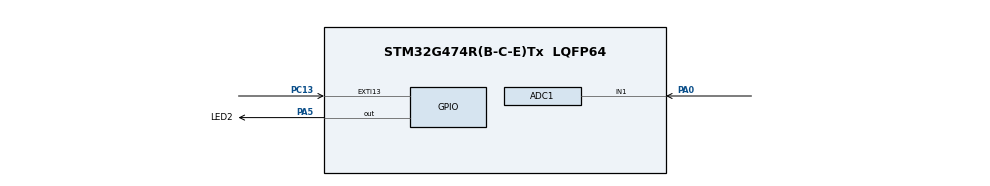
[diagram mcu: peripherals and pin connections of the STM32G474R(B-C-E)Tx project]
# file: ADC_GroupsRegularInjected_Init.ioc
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ADC1.Channel-16\#ChannelRegularConversion=ADC_CHANNEL_1
ADC1.Channel-IN=ADC_CHANNEL_VREFINT
ADC1.ContinuousConvMode=ENABLE
ADC1.DMAContinuousRequests=ENABLE
ADC1.DataAlign=ADC_DATAALIGN_RIGHT
ADC1.DiscontinuousConvMode=DISABLE
ADC1.EOCSelection=ADC_EOC_SINGLE_CONV
ADC1.EnableAnalogWatchDog1=false
ADC1.EnableAnalogWatchDog2=false
ADC1.EnableAnalogWatchDog3=false
ADC1.EnableInjectedConversion=ENABLE
ADC1.EnableInjectedOversampling=ENABLE
ADC1.EnableRegularConversion=ENABLE
ADC1.ExternalTrigConv=ADC_EXTERNALTRIG_T2_TRGO
ADC1.ExternalTrigConvEdge=ADC_EXTERNALTRIGCONVEDGE_RISING
ADC1.ExternalTrigInjecConv=ADC_INJECTED_SOFTWARE_START
ADC1.ExternalTrigInjecConvEdge=ADC_EXTERNALTRIGINJECCONV_EDGE_NONE
ADC1.InjNumberOfConversion=1
ADC1.InjOversamplingRatio=ADC_OVERSAMPLING_RATIO_2
ADC1.InjOversamplingRightShift=ADC_RIGHTBITSHIFT_NONE
ADC1.InjectedChannel-32\#ChannelInjectedConversion=ADC_CHANNEL_VREFINT
ADC1.InjectedConvMode=None
ADC1.InjectedOffsetNumber-32\#ChannelInjectedConversion=ADC_OFFSET_NONE
ADC1.InjectedRank-32\#ChannelInjectedConversion=1
ADC1.InjectedSamplingTime-32\#ChannelInjectedConversion=ADC_SAMPLETIME_640CYCLES_5
ADC1.LowPowerAutoWait=DISABLE
ADC1.NbrOfConversion=1
ADC1.OffsetNumber-16\#ChannelRegularConversion=ADC_OFFSET_NONE
ADC1.Overrun=ADC_OVR_DATA_OVERWRITTEN
ADC1.OversamplingMode=DISABLE
ADC1.Rank-16\#ChannelRegularConversion=1
ADC1.Resolution=ADC_RESOLUTION_12B
ADC1.SamplingTime-16\#ChannelRegularConversion=ADC_SAMPLETIME_47CYCLES_5
ADC1.ScanConvMode=ADC_SCAN_DISABLE
ADC1.injectedQueueMode=DISABLE
ADC1.master=1
Dma.ADC1.0.Direction=DMA_PERIPH_TO_MEMORY
Dma.ADC1.0.EventEnable=DISABLE
Dma.ADC1.0.Instance=DMA1_Channel1
Dma.ADC1.0.MemDataAlignment=DMA_MDATAALIGN_HALFWORD
Dma.ADC1.0.MemInc=DMA_MINC_ENABLE
Dma.ADC1.0.Mode=DMA_CIRCULAR
Dma.ADC1.0.PeriphDataAlignment=DMA_PDATAALIGN_HALFWORD
Dma.ADC1.0.PeriphInc=DMA_PINC_DISABLE
Dma.ADC1.0.Polarity=HAL_DMAMUX_REQ_GEN_RISING
Dma.ADC1.0.Priority=DMA_PRIORITY_HIGH
Dma.ADC1.0.RequestNumber=1
Dma.ADC1.0.SignalID=NONE
Dma.ADC1.0.SyncEnable=DISABLE
Dma.ADC1.0.SyncPolarity=HAL_DMAMUX_SYNC_NO_EVENT
Dma.ADC1.0.SyncRequestNumber=1
Dma.ADC1.0.SyncSignalID=NONE
Dma.Request0=ADC1
Mcu.Family=STM32G4
Mcu.Name=STM32G474R(B-C-E)Tx
Mcu.Package=LQFP64
NVIC.DMA1_Channel1_IRQn=true\:0\:0\:false\:false\:true\:false\:true\:true
NVIC.PriorityGroup=NVIC_PRIORITYGROUP_4
PA0.Mode=IN1-Single-Ended
PA0.Signal=ADC1_IN1
PA5.GPIO_Label=LED2
PA5.Signal=GPIO_Output
PC13.Signal=GPXTI13
ProjectManager.HeapSize=0x200
ProjectManager.StackSize=0x400
ProjectManager.TargetToolchain=EWARM V8.32
RCC.ADC12Freq_Value=150000000
RCC.ADC345Freq_Value=150000000
RCC.AHBFreq_Value=150000000
RCC.APB1Freq_Value=150000000
RCC.APB1TimFreq_Value=150000000
RCC.APB2Freq_Value=150000000
RCC.APB2TimFreq_Value=150000000
RCC.CortexFreq_Value=150000000
RCC.EXTERNAL_CLOCK_VALUE=12288000
RCC.HCLKFreq_Value=150000000
RCC.HSE_VALUE=24000000
RCC.HSI48_VALUE=16000000
RCC.HSI_VALUE=16000000
RCC.LSE_VALUE=32768
RCC.PLLM=RCC_PLLM_DIV4
RCC.PLLN=75
RCC.SYSCLKFreq_VALUE=150000000
RCC.SYSCLKSource=RCC_SYSCLKSOURCE_PLLCLK
RCC.USBFreq_Value=150000000
RCC.VCOOutputFreq_Value=300000000
TIM2.AutoReloadPreload=TIM_AUTORELOAD_PRELOAD_DISABLE
TIM2.ClockDivision=TIM_CLOCKDIVISION_DIV1
TIM2.CounterMode=TIM_COUNTERMODE_UP
TIM2.Period=(timer_reload - 1)
TIM2.Prescaler=(timer_prescaler - 1)
TIM2.TIM_MasterOutputTrigger=TIM_TRGO_UPDATE
TIM2.TIM_MasterSlaveMode=TIM_MASTERSLAVEMODE_DISABLE
TIM2.TIM_SlaveMode=TIM_SLAVEMODE_DISABLE
VP_ADC1_Vref_Input.Mode=IN-Vrefint
VP_SYS_VS_DBSignals.Mode=DisableDeadBatterySignals
VP_TIM2_VS_ClockSourceITR.Mode=TriggerSource_ITR0
board=custom

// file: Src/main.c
/* USER CODE BEGIN Header */
/**
  ******************************************************************************
  * @file    Examples_LL/ADC/ADC_GroupsRegularInjected_Init/Src/main.c
  * @author  MCD Application Team
  * @brief   This example describes how to use a ADC peripheral with
  *          both ADC groups (ADC group regular and ADC group injected)
  *          in their intended use case:
  *           - group regular for a high number of conversions and continuous
  *             data stream, with DMA transfer capability
  *           - group injected for punctual conversions inserted between
  *             conversions of group regular
  *          This example is based on the STM32G4xx ADC LL API;
  *          Peripheral initialization done using LL unitary services functions.
  ******************************************************************************
  * @attention
  *
  * <h2><center>&copy; Copyright (c) 2019 STMicroelectronics.
  * All rights reserved.</center></h2>
  *
  * This software component is licensed by ST under BSD 3-Clause license,
  * the "License"; You may not use this file except in compliance with the
  * License. You may obtain a copy of the License at:
  *                        opensource.org/licenses/BSD-3-Clause
  *
  ******************************************************************************
  */
/* USER CODE END Header */
#include "main.h"

/* USER CODE BEGIN PTD */

/* Definitions of ADC hardware constraints delays */
/* Note: Only ADC IP HW delays are defined in ADC LL driver driver,           */
/*       not timeout values:                                                  */
/*       Timeout values for ADC operations are dependent to device clock      */
/*       configuration (system clock versus ADC clock),                       */
/*       and therefore must be defined in user application.                   */
/*       Refer to @ref ADC_LL_EC_HW_DELAYS for description of ADC timeout     */
/*       values definition.                                                   */

  /* Timeout values for ADC operations. */
  /* (calibration, enable settling time, disable settling time, ...)          */
  /* Values defined to be higher than worst cases: low clock frequency,       */
  /* maximum prescalers.                                                      */
  /* Example of profile very low frequency : ADC clock frequency 0.14MHz      */
  /* prescaler 256, sampling time 247.5 ADC clock cycles, resolution 12 bits. */
  /*  - ADC calibration time: On STM32G4 ADC, maximum delay is 112/fADC,      */
  /*    resulting in a maximum delay of 800us                                 */
  /*    (refer to device datasheet, parameter "tCAL")                         */
  /*  - ADC enable time: maximum delay is 1 conversion cycle.                 */
  /*    (refer to device datasheet, parameter "tSTAB")                        */
  /*  - ADC disable time: maximum delay should be a few ADC clock cycles      */
  /*  - ADC stop conversion time: maximum delay should be a few ADC clock     */
  /*    cycles                                                                */
  /*  - ADC conversion time: with this hypothesis of clock settings, maximum  */
  /*    delay will be 476ms.                                                  */
  /*    (refer to device reference manual, section "Timing")                  */
  /* Unit: ms                                                                 */
  #define ADC_CALIBRATION_TIMEOUT_MS       (   1U)
  #define ADC_ENABLE_TIMEOUT_MS            (   1U)
  #define ADC_DISABLE_TIMEOUT_MS           (   1U)
  #define ADC_STOP_CONVERSION_TIMEOUT_MS   (   1U)
  #define ADC_CONVERSION_TIMEOUT_MS        ( 500U)

  /* Delay between ADC end of calibration and ADC enable.                     */
  /* Delay estimation in CPU cycles: Case of ADC enable done                  */
  /* immediately after ADC calibration, ADC clock setting slow                */
  /* (LL_ADC_CLOCK_ASYNC_DIV32). Use a higher delay if ratio                  */
  /* (CPU clock / ADC clock) is above 32.                                     */
  #define ADC_DELAY_CALIB_ENABLE_CPU_CYCLES  (LL_ADC_DELAY_CALIB_ENABLE_ADC_CYCLES * 32)

/* Definitions of environment analog values */
  /* Value of analog reference voltage (Vref+), connected to analog voltage   */
  /* supply Vdda (unit: mV).                                                  */
  #define VDDA_APPLI                       (3300UL)

/* Definitions of data related to this example */
  /* Definition of ADCx conversions data table size */
  #define ADC_CONVERTED_DATA_BUFFER_SIZE   (  64UL)

  /* Init variable out of expected ADC conversion data range */
  #define VAR_CONVERTED_DATA_INIT_VALUE    (__LL_ADC_DIGITAL_SCALE(LL_ADC_RESOLUTION_12B) + 1)

  /* Parameters of timer (used as ADC conversion trigger) */
  /* Timer frequency (unit: Hz). With a timer 16 bits and time base           */
  /* freq min 1Hz, range is min=1Hz, max=32kHz.                               */
  #define TIMER_FREQUENCY                (1000UL)
  /* Timer minimum frequency (unit: Hz), used to calculate frequency range.   */
  /* With a timer 16 bits, maximum frequency will be 32000 times this value.  */
  #define TIMER_FREQUENCY_RANGE_MIN      (   1UL)
  /* Timer prescaler maximum value (0xFFFF for a timer 16 bits) */
  #define TIMER_PRESCALER_MAX_VALUE      (0xFFFF - 1UL)

/* USER CODE END PTD */

/* USER CODE BEGIN PV */
/* Variables for ADC conversion data */
__IO uint16_t aADCxConvertedData[ADC_CONVERTED_DATA_BUFFER_SIZE];             /* ADC group regular conversion data */
__IO uint16_t uhADCxGrpInjectedConvertedData = VAR_CONVERTED_DATA_INIT_VALUE; /* ADC group injected conversion data */

/* Variables for ADC conversion data computation to physical values */
__IO uint16_t uhADCxGrpInjectedConvertedData_Voltage_mVolt = 0UL;  /* Value of voltage calculated from ADC conversion data (unit: mV) */

/* Variable to report status of DMA transfer of ADC group regular conversions */
/*  0: DMA transfer is not completed                                          */
/*  1: DMA transfer is completed                                              */
/*  2: DMA transfer has not yet been started yet (initial state)              */
__IO uint8_t ubDmaTransferStatus = 2U; /* Variable set into DMA interruption callback */

/* Variable to report status of ADC group injected unitary conversion         */
/*  0: ADC group injected unitary conversion is not completed                 */
/*  1: ADC group injected unitary conversion is completed                     */
/*  2: ADC group injected unitary conversion has not yet been started         */
__IO uint8_t ubAdcGrpInjectedUnitaryConvStatus = 2U; /* Variable set into ADC interruption callback */

/* USER CODE END PV */

void SystemClock_Config(void);
static void MX_GPIO_Init(void);
static void MX_DMA_Init(void);
static void MX_ADC1_Init(void);
static void MX_TIM2_Init(void);
/* USER CODE BEGIN PFP */
void     Activate_ADC(void);
void     LED_On(void);
void     LED_Off(void);
void     LED_Blinking(uint32_t Period);
void     UserButton_Init(void);

/* USER CODE END PFP */

int main(void)
{

  /* MCU Configuration--------------------------------------------------------*/

  /* Reset of all peripherals, Initializes the Flash interface and the Systick. */

  LL_APB2_GRP1_EnableClock(LL_APB2_GRP1_PERIPH_SYSCFG);
  LL_APB1_GRP1_EnableClock(LL_APB1_GRP1_PERIPH_PWR);

  NVIC_SetPriorityGrouping(NVIC_PRIORITYGROUP_4);

  /* System interrupt init*/

  /** Disable the internal Pull-Up in Dead Battery pins of UCPD peripheral
  */
  LL_PWR_DisableUCPDDeadBattery();

  /* Configure the system clock */
  SystemClock_Config();

  /* Initialize all configured peripherals */
  MX_GPIO_Init();
  MX_DMA_Init();
  MX_ADC1_Init();
  MX_TIM2_Init();
  /* USER CODE BEGIN 2 */

  /* Initialize button in EXTI mode */
  UserButton_Init();

  /* Activate ADC */
  /* Perform ADC activation procedure to make it ready to convert. */
  Activate_ADC();

  /* Start ADC group regular conversion */
  /* Note: Hardware constraint (refer to description of the function          */
  /*       below):                                                            */
  /*       On this STM32 serie, setting of this feature is conditioned to     */
  /*       ADC state:                                                         */
  /*       ADC must be enabled without conversion on going on group regular,  */
  /*       without ADC disable command on going.                              */
  /* Note: In this example, all these checks are not necessary but are        */
  /*       implemented anyway to show the best practice usages                */
  /*       corresponding to reference manual procedure.                       */
  /*       Software can be optimized by removing some of these checks, if     */
  /*       they are not relevant considering previous settings and actions    */
  /*       in user application.                                               */
  if ((LL_ADC_IsEnabled(ADC1) == 1)               &&
      (LL_ADC_IsDisableOngoing(ADC1) == 0)        &&
      (LL_ADC_REG_IsConversionOngoing(ADC1) == 0)   )
  {
    LL_ADC_REG_StartConversion(ADC1);
  }
  else
  {
    /* Error: ADC conversion start could not be performed */
    LED_Blinking(LED_BLINK_ERROR);
  }

  /* USER CODE END 2 */

  /* Infinite loop */
  /* USER CODE BEGIN WHILE */
  while (1)
  {
    /* Note: ADC group injected conversion start is done into push button     */
    /*       IRQ handler, refer to function "UserButton_Callback()".          */

    /* Note: LED state depending on ADC conversion status is set into ADC     */
    /*       IRQ handler, refer to function                                   */
    /*       "AdcGrpInjectedUnitaryConvComplete_Callback()".                  */

    /* Note: ADC group regular conversions data are stored into array         */
    /*       "aADCxConvertedData".                                            */
    /*       ADC group injected conversions data are stored into variable     */
    /*       "uhADCxGrpInjectedConvertedData".                                */
    /*       (for debug: see variable content into watch window).             */

    /* Note: ADC conversion data can be computed to physical values           */
    /*       using ADC LL driver helper macro:                                */
    /*         uhADCxConvertedData_Voltage_mVolt                              */
    /*         = __LL_ADC_CALC_DATA_TO_VOLTAGE(VDDA_APPLI,                    */
    /*                                      uhADCxConvertedData),             */
    /*                                      LL_ADC_RESOLUTION_12B)            */

    /* USER CODE END WHILE */

  }
}

void SystemClock_Config(void)
{
  LL_FLASH_SetLatency(LL_FLASH_LATENCY_4);
  while(LL_FLASH_GetLatency() != LL_FLASH_LATENCY_4)
  {
  }
  LL_PWR_SetRegulVoltageScaling(LL_PWR_REGU_VOLTAGE_SCALE1);
  LL_RCC_HSI_Enable();
   /* Wait till HSI is ready */
  while(LL_RCC_HSI_IsReady() != 1)
  {
  }

  LL_RCC_HSI_SetCalibTrimming(64);
  LL_RCC_PLL_ConfigDomain_SYS(LL_RCC_PLLSOURCE_HSI, LL_RCC_PLLM_DIV_4, 75, LL_RCC_PLLR_DIV_2);
  LL_RCC_PLL_EnableDomain_SYS();
  LL_RCC_PLL_Enable();
   /* Wait till PLL is ready */
  while(LL_RCC_PLL_IsReady() != 1)
  {
  }

  LL_RCC_SetSysClkSource(LL_RCC_SYS_CLKSOURCE_PLL);
  LL_RCC_SetAHBPrescaler(LL_RCC_SYSCLK_DIV_2);
   /* Wait till System clock is ready */
  while(LL_RCC_GetSysClkSource() != LL_RCC_SYS_CLKSOURCE_STATUS_PLL)
  {
  }

  /* Insure 1µs transition state at intermediate medium speed clock based on DWT */
  CoreDebug->DEMCR |= CoreDebug_DEMCR_TRCENA_Msk;
  DWT->CTRL |= DWT_CTRL_CYCCNTENA_Msk;
  DWT->CYCCNT = 0;
  while(DWT->CYCCNT < 100);
  /* Set AHB prescaler*/
  LL_RCC_SetAHBPrescaler(LL_RCC_SYSCLK_DIV_1);
  LL_RCC_SetAPB1Prescaler(LL_RCC_APB1_DIV_1);
  LL_RCC_SetAPB2Prescaler(LL_RCC_APB2_DIV_1);

  LL_Init1msTick(150000000);

  LL_SetSystemCoreClock(150000000);
  LL_RCC_SetADCClockSource(LL_RCC_ADC12_CLKSOURCE_SYSCLK);
}

static void MX_ADC1_Init(void)
{

  LL_ADC_InitTypeDef ADC_InitStruct = {0};
  LL_ADC_REG_InitTypeDef ADC_REG_InitStruct = {0};
  LL_ADC_CommonInitTypeDef ADC_CommonInitStruct = {0};
  LL_ADC_INJ_InitTypeDef ADC_INJ_InitStruct = {0};

  LL_GPIO_InitTypeDef GPIO_InitStruct = {0};

  /* Peripheral clock enable */
  LL_AHB2_GRP1_EnableClock(LL_AHB2_GRP1_PERIPH_ADC12);

  LL_AHB2_GRP1_EnableClock(LL_AHB2_GRP1_PERIPH_GPIOA);
  /**ADC1 GPIO Configuration
  PA0   ------> ADC1_IN1
  */
  GPIO_InitStruct.Pin = LL_GPIO_PIN_0;
  GPIO_InitStruct.Mode = LL_GPIO_MODE_ANALOG;
  GPIO_InitStruct.Pull = LL_GPIO_PULL_NO;
  LL_GPIO_Init(GPIOA, &GPIO_InitStruct);

  /* ADC1 DMA Init */

  /* ADC1 Init */
  LL_DMA_SetPeriphRequest(DMA1, LL_DMA_CHANNEL_1, LL_DMAMUX_REQ_ADC1);

  LL_DMA_SetDataTransferDirection(DMA1, LL_DMA_CHANNEL_1, LL_DMA_DIRECTION_PERIPH_TO_MEMORY);

  LL_DMA_SetChannelPriorityLevel(DMA1, LL_DMA_CHANNEL_1, LL_DMA_PRIORITY_HIGH);

  LL_DMA_SetMode(DMA1, LL_DMA_CHANNEL_1, LL_DMA_MODE_CIRCULAR);

  LL_DMA_SetPeriphIncMode(DMA1, LL_DMA_CHANNEL_1, LL_DMA_PERIPH_NOINCREMENT);

  LL_DMA_SetMemoryIncMode(DMA1, LL_DMA_CHANNEL_1, LL_DMA_MEMORY_INCREMENT);

  LL_DMA_SetPeriphSize(DMA1, LL_DMA_CHANNEL_1, LL_DMA_PDATAALIGN_HALFWORD);

  LL_DMA_SetMemorySize(DMA1, LL_DMA_CHANNEL_1, LL_DMA_MDATAALIGN_HALFWORD);

  /* USER CODE BEGIN ADC1_Init 1 */

  /* Select ADC as DMA transfer request */
  LL_DMA_SetPeriphRequest(DMA1,
                          LL_DMA_CHANNEL_1,
                          LL_DMAMUX_REQ_ADC1);

  /* Set DMA transfer addresses of source and destination */
  LL_DMA_ConfigAddresses(DMA1,
                         LL_DMA_CHANNEL_1,
                         LL_ADC_DMA_GetRegAddr(ADC1, LL_ADC_DMA_REG_REGULAR_DATA),
                         (uint32_t)&aADCxConvertedData,
                         LL_DMA_DIRECTION_PERIPH_TO_MEMORY);

  /* Set DMA transfer size */
  LL_DMA_SetDataLength(DMA1,
                       LL_DMA_CHANNEL_1,
                       ADC_CONVERTED_DATA_BUFFER_SIZE);

  /* Enable DMA transfer interruption: transfer complete */
  LL_DMA_EnableIT_TC(DMA1,
                       LL_DMA_CHANNEL_1);

  /* Enable DMA transfer interruption: half transfer */
  LL_DMA_EnableIT_HT(DMA1,
                        LL_DMA_CHANNEL_1);

  /* Enable DMA transfer interruption: transfer error */
  LL_DMA_EnableIT_TE(DMA1,
                     LL_DMA_CHANNEL_1);

  /*## Activation of DMA #####################################################*/
  /* Enable the DMA transfer */
  LL_DMA_EnableChannel(DMA1,
                       LL_DMA_CHANNEL_1);

  /*## Configuration of GPIO used by ADC channels ############################*/

  /* Note: On this STM32 device, ADC1 channel 1 is mapped on GPIO pin PA.00 */

  /* Configure GPIO in analog mode to be used as ADC input */
  LL_GPIO_SetPinMode(GPIOA, LL_GPIO_PIN_0, LL_GPIO_MODE_ANALOG);

  /*## Configuration of NVIC #################################################*/
  /* Configure NVIC to enable ADC1 interruptions */
  NVIC_SetPriority(ADC1_2_IRQn, 0);
  NVIC_EnableIRQ(ADC1_2_IRQn);
  /* USER CODE END ADC1_Init 1 */
  /** Common config
  */
  ADC_InitStruct.Resolution = LL_ADC_RESOLUTION_12B;
  ADC_InitStruct.DataAlignment = LL_ADC_DATA_ALIGN_RIGHT;
  ADC_InitStruct.LowPowerMode = LL_ADC_LP_MODE_NONE;
  LL_ADC_Init(ADC1, &ADC_InitStruct);
  ADC_REG_InitStruct.TriggerSource = LL_ADC_REG_TRIG_EXT_TIM2_TRGO;
  ADC_REG_InitStruct.SequencerLength = LL_ADC_REG_SEQ_SCAN_DISABLE;
  ADC_REG_InitStruct.SequencerDiscont = LL_ADC_REG_SEQ_DISCONT_DISABLE;
  ADC_REG_InitStruct.ContinuousMode = LL_ADC_REG_CONV_CONTINUOUS;
  ADC_REG_InitStruct.DMATransfer = LL_ADC_REG_DMA_TRANSFER_UNLIMITED;
  ADC_REG_InitStruct.Overrun = LL_ADC_REG_OVR_DATA_OVERWRITTEN;
  LL_ADC_REG_Init(ADC1, &ADC_REG_InitStruct);
  LL_ADC_SetGainCompensation(ADC1, 0);
  LL_ADC_SetOverSamplingScope(ADC1, LL_ADC_OVS_GRP_INJECTED);
  ADC_CommonInitStruct.CommonClock = LL_ADC_CLOCK_SYNC_PCLK_DIV4;
  ADC_CommonInitStruct.Multimode = LL_ADC_MULTI_INDEPENDENT;
  LL_ADC_CommonInit(__LL_ADC_COMMON_INSTANCE(ADC1), &ADC_CommonInitStruct);
  ADC_INJ_InitStruct.TriggerSource = LL_ADC_INJ_TRIG_SOFTWARE;
  ADC_INJ_InitStruct.SequencerLength = LL_ADC_INJ_SEQ_SCAN_DISABLE;
  ADC_INJ_InitStruct.SequencerDiscont = LL_ADC_INJ_SEQ_DISCONT_DISABLE;
  ADC_INJ_InitStruct.TrigAuto = LL_ADC_INJ_TRIG_INDEPENDENT;
  LL_ADC_INJ_Init(ADC1, &ADC_INJ_InitStruct);
  LL_ADC_INJ_SetQueueMode(ADC1, LL_ADC_INJ_QUEUE_DISABLE);
  LL_ADC_ConfigOverSamplingRatioShift(ADC1, LL_ADC_OVS_RATIO_2, LL_ADC_OVS_SHIFT_NONE);
  LL_ADC_REG_SetTriggerEdge(ADC1, LL_ADC_REG_TRIG_EXT_RISING);

  /* Disable ADC deep power down (enabled by default after reset state) */
  LL_ADC_DisableDeepPowerDown(ADC1);
  /* Enable ADC internal voltage regulator */
  LL_ADC_EnableInternalRegulator(ADC1);
  /* Delay for ADC internal voltage regulator stabilization. */
  /* Compute number of CPU cycles to wait for, from delay in us. */
  /* Note: Variable divided by 2 to compensate partially */
  /* CPU processing cycles (depends on compilation optimization). */
  /* Note: If system core clock frequency is below 200kHz, wait time */
  /* is only a few CPU processing cycles. */
  uint32_t wait_loop_index;
  wait_loop_index = ((LL_ADC_DELAY_INTERNAL_REGUL_STAB_US * (SystemCoreClock / (100000 * 2))) / 10);
  while(wait_loop_index != 0)
  {
    wait_loop_index--;
  }
  /** Configure Regular Channel
  */
  LL_ADC_REG_SetSequencerRanks(ADC1, LL_ADC_REG_RANK_1, LL_ADC_CHANNEL_1);
  LL_ADC_SetChannelSamplingTime(ADC1, LL_ADC_CHANNEL_1, LL_ADC_SAMPLINGTIME_47CYCLES_5);
  LL_ADC_SetChannelSingleDiff(ADC1, LL_ADC_CHANNEL_1, LL_ADC_SINGLE_ENDED);
  /** Configure Injected Channel
  */
  LL_ADC_INJ_SetSequencerRanks(ADC1, LL_ADC_INJ_RANK_1, LL_ADC_CHANNEL_VREFINT);
  LL_ADC_SetChannelSamplingTime(ADC1, LL_ADC_CHANNEL_VREFINT, LL_ADC_SAMPLINGTIME_640CYCLES_5);
  LL_ADC_SetChannelSingleDiff(ADC1, LL_ADC_CHANNEL_VREFINT, LL_ADC_SINGLE_ENDED);
  LL_ADC_SetCommonPathInternalCh(__LL_ADC_COMMON_INSTANCE(ADC1), LL_ADC_PATH_INTERNAL_VREFINT);
  /* USER CODE BEGIN ADC1_Init 2 */

  /* Configuration of ADC interruptions */
  /* Enable interruption ADC group regular end of unitary conversion */
  LL_ADC_EnableIT_EOC(ADC1);
  LL_ADC_DisableIT_EOS(ADC1);

  /* Enable interruption ADC group end of injected conversion */
  LL_ADC_EnableIT_JEOC(ADC1);
  LL_ADC_DisableIT_JEOS(ADC1);

  /* USER CODE END ADC1_Init 2 */

}

static void MX_TIM2_Init(void)
{

  /* USER CODE BEGIN TIM2_Init 0 */

  uint32_t timer_clock_frequency = 0;             /* Timer clock frequency */
  uint32_t timer_prescaler = 0;                   /* Time base prescaler to have timebase aligned on minimum frequency possible */
  uint32_t timer_reload = 0;                      /* Timer reload value in function of timer prescaler to achieve time base period */

  /* USER CODE END TIM2_Init 0 */

  LL_TIM_InitTypeDef TIM_InitStruct = {0};

  /* Peripheral clock enable */
  LL_APB1_GRP1_EnableClock(LL_APB1_GRP1_PERIPH_TIM2);

  /* USER CODE BEGIN TIM2_Init 1 */

  /*## Configuration of NVIC #################################################*/
  /* Note: In this example, timer interrupts are not activated.               */
  /*       If needed, timer interruption at each time base period is          */
  /*       possible.                                                          */
  /*       Refer to timer examples.                                           */

  /* Note: In this example, timer interrupts are not activated */
  /*       If needed, timer interruption at each time base     */
  /*       period is possible.                                 */
  /*       Refer to timer examples.                            */

  /* Configuration of timer as time base:                                     */
  /* Caution: Computation of frequency is done for a timer instance on APB1   */
  /*          (clocked by PCLK1)                                              */
  /* Timer frequency is configured from the following constants:              */
  /* - TIMER_FREQUENCY: timer frequency (unit: Hz).                           */
  /* - TIMER_FREQUENCY_RANGE_MIN: timer minimum frequency possible            */
  /*   (unit: Hz).                                                            */
  /* Note: Refer to comments at these literals definition for more details.   */

  /* Retrieve timer clock source frequency */
  /* If APB1 prescaler is different of 1, timers have a factor x2 on their    */
  /* clock source.                                                            */
  if (LL_RCC_GetAPB1Prescaler() == LL_RCC_APB1_DIV_1)
  {
    timer_clock_frequency = __LL_RCC_CALC_PCLK1_FREQ(SystemCoreClock, LL_RCC_GetAPB1Prescaler());
  }
  else
  {
    timer_clock_frequency = (__LL_RCC_CALC_PCLK1_FREQ(SystemCoreClock, LL_RCC_GetAPB1Prescaler()) * 2);
  }

  /* Timer prescaler calculation */
  /* (computation for timer 16 bits, additional + 1 to round the prescaler up) */
  timer_prescaler = ((timer_clock_frequency / (TIMER_PRESCALER_MAX_VALUE * TIMER_FREQUENCY_RANGE_MIN)) +1);
  /* Timer reload calculation */
  timer_reload = (timer_clock_frequency / (timer_prescaler * TIMER_FREQUENCY));

  /* USER CODE END TIM2_Init 1 */
  TIM_InitStruct.Prescaler = (timer_prescaler - 1);
  TIM_InitStruct.CounterMode = LL_TIM_COUNTERMODE_UP;
  TIM_InitStruct.Autoreload = (timer_reload - 1);
  TIM_InitStruct.ClockDivision = LL_TIM_CLOCKDIVISION_DIV1;
  LL_TIM_Init(TIM2, &TIM_InitStruct);
  LL_TIM_DisableARRPreload(TIM2);
  LL_TIM_SetTriggerInput(TIM2, LL_TIM_TS_ITR0);
  LL_TIM_SetSlaveMode(TIM2, LL_TIM_SLAVEMODE_DISABLED);
  LL_TIM_DisableIT_TRIG(TIM2);
  LL_TIM_DisableDMAReq_TRIG(TIM2);
  LL_TIM_SetTriggerOutput(TIM2, LL_TIM_TRGO_UPDATE);
  LL_TIM_DisableMasterSlaveMode(TIM2);
  /* USER CODE BEGIN TIM2_Init 2 */
  /* Note: In this example, timer interrupts are not activated.               */
  /*       If needed, timer interruption at each time base period is          */
  /*       possible.                                                          */
  /*       Refer to timer examples.                                           */

  /* Set timer the trigger output (TRGO) */
  LL_TIM_SetTriggerOutput(TIM2, LL_TIM_TRGO_UPDATE);

  /* Enable counter */
  LL_TIM_EnableCounter(TIM2);
  /* USER CODE END TIM2_Init 2 */

}

static void MX_DMA_Init(void)
{

  /* Init with LL driver */
  /* DMA controller clock enable */
  LL_AHB1_GRP1_EnableClock(LL_AHB1_GRP1_PERIPH_DMAMUX1);
  LL_AHB1_GRP1_EnableClock(LL_AHB1_GRP1_PERIPH_DMA1);

  /* DMA interrupt init */
  /* DMA1_Channel1_IRQn interrupt configuration */
  NVIC_SetPriority(DMA1_Channel1_IRQn, NVIC_EncodePriority(NVIC_GetPriorityGrouping(),0, 0));
  NVIC_EnableIRQ(DMA1_Channel1_IRQn);

}

static void MX_GPIO_Init(void)
{
  LL_EXTI_InitTypeDef EXTI_InitStruct = {0};
  LL_GPIO_InitTypeDef GPIO_InitStruct = {0};

  /* GPIO Ports Clock Enable */
  LL_AHB2_GRP1_EnableClock(LL_AHB2_GRP1_PERIPH_GPIOC);
  LL_AHB2_GRP1_EnableClock(LL_AHB2_GRP1_PERIPH_GPIOA);

  /**/
  LL_GPIO_ResetOutputPin(LED2_GPIO_Port, LED2_Pin);

  /**/
  LL_SYSCFG_SetEXTISource(LL_SYSCFG_EXTI_PORTC, LL_SYSCFG_EXTI_LINE13);

  /**/
  EXTI_InitStruct.Line_0_31 = LL_EXTI_LINE_13;
  EXTI_InitStruct.LineCommand = ENABLE;
  EXTI_InitStruct.Mode = LL_EXTI_MODE_IT;
  EXTI_InitStruct.Trigger = LL_EXTI_TRIGGER_RISING;
  LL_EXTI_Init(&EXTI_InitStruct);

  /**/
  LL_GPIO_SetPinPull(GPIOC, LL_GPIO_PIN_13, LL_GPIO_PULL_NO);

  /**/
  LL_GPIO_SetPinMode(GPIOC, LL_GPIO_PIN_13, LL_GPIO_MODE_INPUT);

  /**/
  GPIO_InitStruct.Pin = LED2_Pin;
  GPIO_InitStruct.Mode = LL_GPIO_MODE_OUTPUT;
  GPIO_InitStruct.Speed = LL_GPIO_SPEED_FREQ_LOW;
  GPIO_InitStruct.OutputType = LL_GPIO_OUTPUT_PUSHPULL;
  GPIO_InitStruct.Pull = LL_GPIO_PULL_NO;
  LL_GPIO_Init(LED2_GPIO_Port, &GPIO_InitStruct);

}

/* USER CODE BEGIN 4 */
/**
  * @brief  Perform ADC activation procedure to make it ready to convert
  *         (ADC instance: ADC1).
  * @note   Operations:
  *         - ADC instance
  *           - Disable deep power down
  *           - Enable internal voltage regulator
  *           - Run ADC self calibration
  *           - Enable ADC
  *         - ADC group regular
  *           none: ADC conversion start-stop to be performed
  *                 after this function
  *         - ADC group injected
  *           none: ADC conversion start-stop to be performed
  *                 after this function
  * @param  None
  * @retval None
  */
void Activate_ADC(void)
{
  __IO uint32_t wait_loop_index = 0U;
  #if (USE_TIMEOUT == 1)
  uint32_t Timeout = 0U; /* Variable used for timeout management */
  #endif /* USE_TIMEOUT */

  /*## Operation on ADC hierarchical scope: ADC instance #####################*/

  /* Note: Hardware constraint (refer to description of the functions         */
  /*       below):                                                            */
  /*       On this STM32 serie, setting of these features is conditioned to   */
  /*       ADC state:                                                         */
  /*       ADC must be disabled.                                              */
  /* Note: In this example, all these checks are not necessary but are        */
  /*       implemented anyway to show the best practice usages                */
  /*       corresponding to reference manual procedure.                       */
  /*       Software can be optimized by removing some of these checks, if     */
  /*       they are not relevant considering previous settings and actions    */
  /*       in user application.                                               */
  if (LL_ADC_IsEnabled(ADC1) == 0)
  {
    /* Disable ADC deep power down (enabled by default after reset state) */
    LL_ADC_DisableDeepPowerDown(ADC1);

    /* Enable ADC internal voltage regulator */
    LL_ADC_EnableInternalRegulator(ADC1);

    /* Delay for ADC internal voltage regulator stabilization.                */
    /* Compute number of CPU cycles to wait for, from delay in us.            */
    /* Note: Variable divided by 2 to compensate partially                    */
    /*       CPU processing cycles (depends on compilation optimization).     */
    /* Note: If system core clock frequency is below 200kHz, wait time        */
    /*       is only a few CPU processing cycles.                             */
    wait_loop_index = ((LL_ADC_DELAY_INTERNAL_REGUL_STAB_US * (SystemCoreClock / (100000 * 2))) / 10);
    while(wait_loop_index != 0)
    {
      wait_loop_index--;
    }

    /* Run ADC self calibration */
    LL_ADC_StartCalibration(ADC1, LL_ADC_SINGLE_ENDED);

    /* Poll for ADC effectively calibrated */
    #if (USE_TIMEOUT == 1)
    Timeout = ADC_CALIBRATION_TIMEOUT_MS;
    #endif /* USE_TIMEOUT */

    while (LL_ADC_IsCalibrationOnGoing(ADC1) != 0)
    {
    #if (USE_TIMEOUT == 1)
      /* Check Systick counter flag to decrement the time-out value */
      if (LL_SYSTICK_IsActiveCounterFlag())
      {
        if(Timeout-- == 0)
        {
        /* Time-out occurred. Set LED to blinking mode */
        LED_Blinking(LED_BLINK_ERROR);
        }
      }
    #endif /* USE_TIMEOUT */
    }

    /* Delay between ADC end of calibration and ADC enable.                   */
    /* Note: Variable divided by 2 to compensate partially                    */
    /*       CPU processing cycles (depends on compilation optimization).     */
    wait_loop_index = (ADC_DELAY_CALIB_ENABLE_CPU_CYCLES >> 1);
    while(wait_loop_index != 0)
    {
      wait_loop_index--;
    }

    /* Enable ADC */
    LL_ADC_Enable(ADC1);

    /* Poll for ADC ready to convert */
    #if (USE_TIMEOUT == 1)
    Timeout = ADC_ENABLE_TIMEOUT_MS;
    #endif /* USE_TIMEOUT */

    while (LL_ADC_IsActiveFlag_ADRDY(ADC1) == 0)
    {
    #if (USE_TIMEOUT == 1)
      /* Check Systick counter flag to decrement the time-out value */
      if (LL_SYSTICK_IsActiveCounterFlag())
      {
        if(Timeout-- == 0)
        {
        /* Time-out occurred. Set LED to blinking mode */
        LED_Blinking(LED_BLINK_ERROR);
        }
      }
    #endif /* USE_TIMEOUT */
    }

    /* Note: ADC flag ADRDY is not cleared here to be able to check ADC       */
    /*       status afterwards.                                               */
    /*       This flag should be cleared at ADC Deactivation, before a new    */
    /*       ADC activation, using function "LL_ADC_ClearFlag_ADRDY()".       */
  }

  /*## Operation on ADC hierarchical scope: ADC group regular ################*/
  /* Note: No operation on ADC group regular performed here.                  */
  /*       ADC group regular conversions to be performed after this function  */
  /*       using function:                                                    */
  /*       "LL_ADC_REG_StartConversion();"                                    */

  /*## Operation on ADC hierarchical scope: ADC group injected ###############*/
  /* Note: No operation on ADC group injected performed here.                 */
  /*       ADC group injected conversions to be performed after this function */
  /*       using function:                                                    */
  /*       "LL_ADC_INJ_StartConversion();"                                    */

}

/**
  * @brief  Turn-on LED2.
  * @param  None
  * @retval None
  */
void LED_On(void)
{
  /* Turn LED2 on */
  LL_GPIO_SetOutputPin(LED2_GPIO_Port, LED2_Pin);
}

/**
  * @brief  Turn-off LED2.
  * @param  None
  * @retval None
  */
void LED_Off(void)
{
  /* Turn LED2 off */
  LL_GPIO_ResetOutputPin(LED2_GPIO_Port, LED2_Pin);
}

/**
  * @brief  Set LED2 to Blinking mode for an infinite loop (toggle period based on value provided as input parameter).
  * @param  Period : Period of time (in ms) between each toggling of LED
  *   This parameter can be user defined values. Pre-defined values used in that example are :
  *     @arg LED_BLINK_FAST : Fast Blinking
  *     @arg LED_BLINK_SLOW : Slow Blinking
  *     @arg LED_BLINK_ERROR : Error specific Blinking
  * @retval None
  */
void LED_Blinking(uint32_t Period)
{
  /* Turn LED2 on */
  LL_GPIO_SetOutputPin(LED2_GPIO_Port, LED2_Pin);

  /* Toggle IO in an infinite loop */
  while (1)
  {
    LL_GPIO_TogglePin(LED2_GPIO_Port, LED2_Pin);
    LL_mDelay(Period);
  }
}

/**
  * @brief  Configures User push-button in EXTI Line Mode.
  * @param  None
  * @retval None
  */
void UserButton_Init(void)
{
  /* Enable the BUTTON Clock */
  USER_BUTTON_GPIO_CLK_ENABLE();

  /* Configure GPIO for BUTTON */
  LL_GPIO_SetPinMode(USER_BUTTON_GPIO_PORT, USER_BUTTON_PIN, LL_GPIO_MODE_INPUT);
  LL_GPIO_SetPinPull(USER_BUTTON_GPIO_PORT, USER_BUTTON_PIN, LL_GPIO_PULL_DOWN);

  /* if(Button_Mode == BUTTON_MODE_EXTI) */
  {
    /* Connect External Line to the GPIO */
    USER_BUTTON_SYSCFG_SET_EXTI();

    /* Enable a rising trigger EXTI line 13 Interrupt */
    USER_BUTTON_EXTI_LINE_ENABLE();
    USER_BUTTON_EXTI_FALLING_TRIG_ENABLE();

    /* Configure NVIC for USER_BUTTON_EXTI_IRQn */
    NVIC_EnableIRQ(USER_BUTTON_EXTI_IRQn);
    NVIC_SetPriority(USER_BUTTON_EXTI_IRQn,0x03);
  }
}

/******************************************************************************/
/*   USER IRQ HANDLER TREATMENT                                               */
/******************************************************************************/

/**
  * @brief  Function to manage IRQ Handler
  * @param  None
  * @retval None
  */
void UserButton_Callback(void)
{
  /* Turn LED off before performing a new ADC conversion start */
  LED_Off();

  /* Reset status variable of ADC group injected unitary conversion before    */
  /* peforming a new ADC group injected conversion start.                     */
  /* Note: Optionally, for this example purpose, check ADC unitary            */
  /*       conversion status before starting another ADC conversion.          */

  if (ubAdcGrpInjectedUnitaryConvStatus != 0)
  {
    ubAdcGrpInjectedUnitaryConvStatus = 0;
  }
  else
  {
    /* Error: Previous action (ADC conversion or DMA transfer) not yet        */
    /* completed.                                                             */
    LED_Blinking(LED_BLINK_ERROR);
  }

  /* Init variable containing ADC conversion data */
  uhADCxGrpInjectedConvertedData = VAR_CONVERTED_DATA_INIT_VALUE;

  /* Start ADC group injected conversion */
  /* Note: Hardware constraint (refer to description of the function          */
  /*       below):                                                            */
  /*       On this STM32 serie, setting of this feature is conditioned to     */
  /*       ADC state:                                                         */
  /*       ADC must be enabled without conversion on going on group injected, */
  /*       without ADC disable command on going.                              */
  /* Note: In this example, all these checks are not necessary but are        */
  /*       implemented anyway to show the best practice usages                */
  /*       corresponding to reference manual procedure.                       */
  /*       Software can be optimized by removing some of these checks, if     */
  /*       they are not relevant considering previous settings and actions    */
  /*       in user application.                                               */
  if ((LL_ADC_IsEnabled(ADC1) == 1)               &&
      (LL_ADC_IsDisableOngoing(ADC1) == 0)        &&
      (LL_ADC_INJ_IsConversionOngoing(ADC1) == 0)   )
  {
    LL_ADC_INJ_StartConversion(ADC1);
  }
  else
  {
    /* Error: ADC conversion start could not be performed */
    LED_Blinking(LED_BLINK_ERROR);
  }
}

/**
  * @brief  DMA transfer complete callback
  * @note   This function is executed when the transfer complete interrupt
  *         is generated
  * @retval None
  */
void AdcDmaTransferComplete_Callback()
{
  /* Update status variable of DMA transfer */
  ubDmaTransferStatus = 1;
}

/**
  * @brief  DMA half transfer callback
  * @note   This function is executed when the half transfer interrupt
  *         is generated
  * @retval None
  */
void AdcDmaTransferHalf_Callback()
{
  /* Update status variable of DMA transfer */
  ubDmaTransferStatus = 0;
}

/**
  * @brief  DMA transfer error callback
  * @note   This function is executed when the transfer error interrupt
  *         is generated during DMA transfer
  * @retval None
  */
void AdcDmaTransferError_Callback()
{
  if(ubDmaTransferStatus == 1)
  {
    /* Update status variable of DMA transfer */
    ubDmaTransferStatus = 0;
  }

  /* Error detected during DMA transfer */
  LED_Blinking(LED_BLINK_ERROR);
}

/**
  * @brief  ADC group regular overrun interruption callback
  * @note   This function is executed when ADC group regular
  *         overrun error occurs.
  * @retval None
  */
void AdcGrpRegularOverrunError_Callback(void)
{
  /* Note: Disable ADC interruption that caused this error before entering in */
  /*       infinite loop below.                                               */

  /* Disable ADC group regular overrun interruption */
  LL_ADC_DisableIT_OVR(ADC1);

  /* Error from ADC */
  LED_Blinking(LED_BLINK_ERROR);
}

/**
  * @brief  ADC group injected end of unitary conversion interruption callback
  * @note   This function is executed when the ADC group injected
  *         sequencer has converted one ranks of the sequence.
  * @retval None
  */
void AdcGrpInjectedUnitaryConvComplete_Callback()
{
  /* Retrieve ADC conversion data */
  /* (data maximum amplitude corresponds to ADC resolution: 12 bits) */
  uhADCxGrpInjectedConvertedData = LL_ADC_INJ_ReadConversionData12(ADC1, LL_ADC_INJ_RANK_1);

  /* Computation of ADC conversions raw data to physical values               */
  /* using LL ADC driver helper macro.                                        */
  uhADCxGrpInjectedConvertedData_Voltage_mVolt = __LL_ADC_CALC_DATA_TO_VOLTAGE(VDDA_APPLI, uhADCxGrpInjectedConvertedData, LL_ADC_RESOLUTION_12B);

  /* Update status variable of ADC unitary conversion */
  ubAdcGrpInjectedUnitaryConvStatus = 1;

  /* Set LED depending on ADC unitary conversion status */
  /* - Turn-on if ADC group injected unitary conversion is completed */
  /* - Turn-off if ADC group injected unitary conversion is not completed */
  LED_On();

}

/* USER CODE END 4 */

void Error_Handler(void)
{
}

/************************ (C) COPYRIGHT STMicroelectronics *****END OF FILE****/
